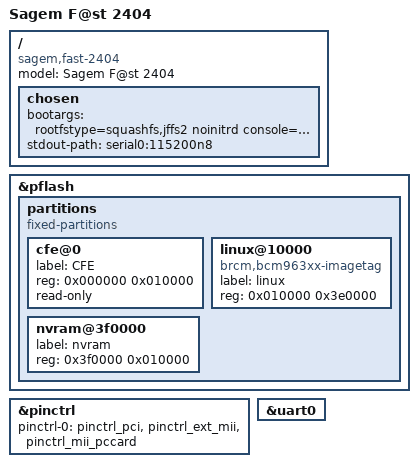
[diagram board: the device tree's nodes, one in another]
#include "bcm6348.dtsi"

#include <dt-bindings/input/input.h>

/ {
	model = "Sagem F@st 2404";
	compatible = "sagem,fast-2404", "brcm,bcm6348";

	chosen {
		bootargs = "rootfstype=squashfs,jffs2 noinitrd console=ttyS0,115200";
		stdout-path = "serial0:115200n8";
	};
};

&pflash {
	status = "okay";

	partitions {
		compatible = "fixed-partitions";
		#address-cells = <1>;
		#size-cells = <1>;

		cfe@0 {
			label = "CFE";
			reg = <0x000000 0x010000>;
			read-only;
		};

		linux@10000 {
			label = "linux";
			reg = <0x010000 0x3e0000>;
			compatible = "brcm,bcm963xx-imagetag";
		};

		nvram@3f0000 {
			label = "nvram";
			reg = <0x3f0000 0x010000>;
		};
	};
};

&pinctrl {
	pinctrl-names = "default";
	pinctrl-0 = <&pinctrl_pci &pinctrl_ext_mii &pinctrl_mii_pccard>;
};

&uart0 {
	status = "okay";
};
